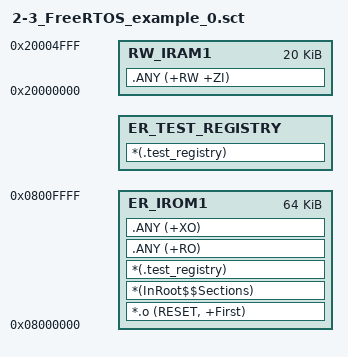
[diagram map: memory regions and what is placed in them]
; *************************************************************
; *** Scatter-Loading Description File generated by uVision ***
; *************************************************************

LR_IROM1 0x08000000 0x00010000  {    ; 加载区
  ER_IROM1 0x08000000 0x00010000  {  ; 代码/只读数据区
   *.o (RESET, +First)
   *(InRoot$$Sections)
   *(.test_registry)               ; 把测试用例先放进来保证连续（可选）
   .ANY (+RO)
   .ANY (+XO)
  }
  ; 新增独立的测试注册执行区，紧跟 ER_IROM1，但无实际代码
  ER_TEST_REGISTRY +0  {
    *(.test_registry)              ; 所有 .test_registry 段放在这里
  }
  RW_IRAM1 0x20000000 0x00005000  {
   .ANY (+RW +ZI)
  }
}
